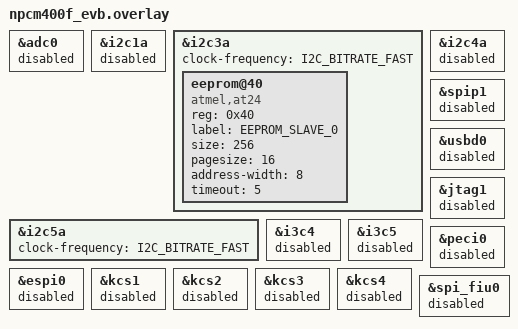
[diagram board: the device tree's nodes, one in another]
&adc0 {
    status = "disabled";
};

&i2c1a {
	status = "disabled";
};

&i2c3a {
    status = "okay";
    clock-frequency = <I2C_BITRATE_FAST>;

	eeprom@40 {
        compatible = "atmel,at24";
        reg = <0x40>;
        label = "EEPROM_SLAVE_0";
        size = <256>;
        pagesize = <16>;
        address-width = <8>;
        timeout = <5>;
        status = "okay";
    };
};

&i2c4a {
	status = "disabled";
};

&i2c5a {
	clock-frequency = <I2C_BITRATE_FAST>;
	status = "okay";
};

&spip1 {
    status = "disabled";
};

&usbd0 {
    status = "disabled";
};

&jtag1 {
    status = "disabled";
};

&i3c4 {
    status = "disabled";
};

&i3c5 {
    status = "disabled";
};

&peci0 {
    status = "disabled";
};

&espi0 {
    status = "disabled";
};

&kcs1 {
    status = "disabled";
};

&kcs2 {
    status = "disabled";
};

&kcs3 {
    status = "disabled";
};

&kcs4 {
    status = "disabled";
};

&spi_fiu0 {
    status = "disabled";
};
